# R7FA6M4AF register map
Vendor: Renesas Electronics Corporation; Series: RA6; File version: 1.20.04
CPU: CM33 r0p4, little endian, MPU, FPU, VTOR, 4 interrupt priority bits, 96 interrupts
Registers are 8-bit, read-write, reset 0x0 unless marked. A register's access mark holds for its fields unless they carry their own. Offsets are from the block's base; [hi:lo] are bit positions; {n}, {i} and the like mark numbered series.

## RMPU — Renesas Memory Protection Unit
Base 0x40000000
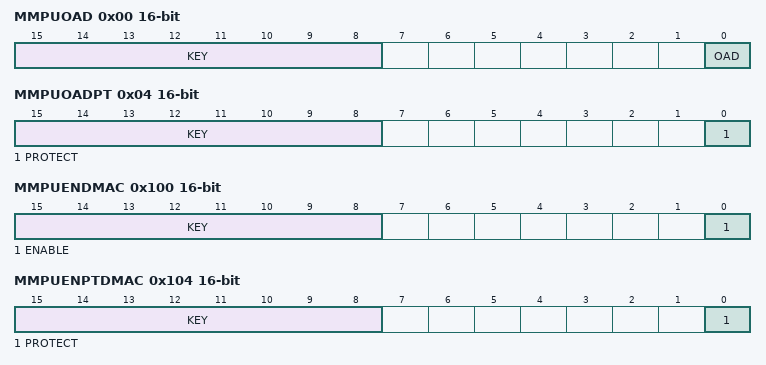
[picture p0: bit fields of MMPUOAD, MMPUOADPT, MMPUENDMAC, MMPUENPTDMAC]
0x00 MMPUOAD 16-bit — MMPU Operation After Detection Register
  [15:8] KEY wo — This bit enables or disables writes to the OAD bit.
  [0] OAD — Operation after detection
    0=Non-maskable interrupt; 1=Reset
0x04 MMPUOADPT 16-bit — MMPU Operation After Detection Protect Register
  [15:8] KEY wo — Key code
  [0] PROTECT — Protection of register
    0=MMPUOAD register writes are possible; 1=MMPUOAD register writes are protected. Read is possible.
0x100 MMPUENDMAC 16-bit — MMPU Enable Register for DMAC
  [15:8] KEY wo — These bits enable or disable writes to the ENABLE bit.
  [0] ENABLE — Bus Master MPU of DMAC enable
    0=Bus Master MPU of DMAC is disabled; 1=Bus Master MPU of DMAC is enabled
0x104 MMPUENPTDMAC 16-bit — MMPU Enable Protect Register for DMAC
  [15:8] KEY wo — These bits enable or disable writes to the PROTECT bit.
  [0] PROTECT — Protection of register
    0=MMPUENDMAC register writes are possible; 1=MMPUENDMAC register writes are protected. Read is possible.
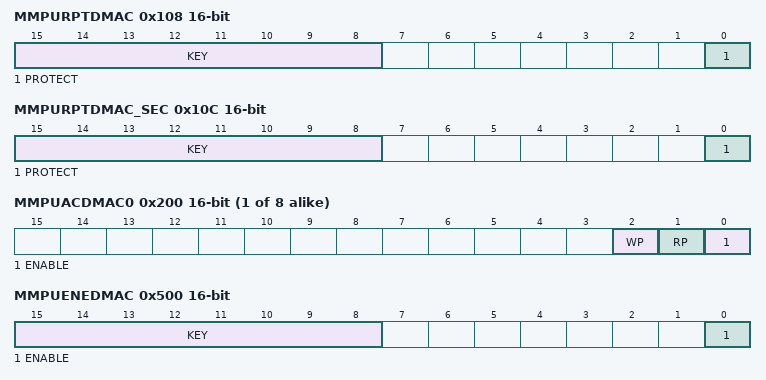
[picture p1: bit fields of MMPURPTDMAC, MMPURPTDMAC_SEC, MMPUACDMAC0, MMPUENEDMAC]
0x108 MMPURPTDMAC 16-bit — MMPU Regions Protect Register for DMAC
  [15:8] KEY wo — These bits enable or disable writes to the PROTECT bit.
  [0] PROTECT — Protection of register
    0=Bus Master MPU register for DMAC writing is possible; 1=Bus Master MPU register for DMAC writing is protected. Read is possible.
0x10C MMPURPTDMAC_SEC 16-bit — MMPU Regions Protect register for DMAC Secure
  [15:8] KEY wo — These bits enable or disable writes to the PROTECT bit.
  [0] PROTECT — Protection of register
    0=Bus master MPU register for DMAC secure writes are possible; 1=Bus master MPU register for DMAC secure writes are protected. Read is possible.
{0x200+0x10*i} MMPUACDMAC{i} (i=0..7) 16-bit — MMPU Access Control Register for DMAC
  [2] WP — Write protection
    0=Write permission; 1=Write protection
  [1] RP — Read protection
    0=Read permission; 1=Read protection
  [0] ENABLE — Region enable
    0=DMAC Region n unit is disabled; 1=DMAC Region n unit is enabled
{0x204+0x10*i} MMPUSDMAC{i} (i=0..7) 32-bit (reset mask 0x1F) — MMPU Start Address Register for DMAC
  [31:5] MMPUS — Region start address register
{0x208+0x10*i} MMPUEDMAC{i} (i=0..7) 32-bit reset 0x1F (reset mask 0x1F) — MMPU End Address Register for DMAC
  [31:5] MMPUE — Region end address register
0x500 MMPUENEDMAC 16-bit — MMPU Enable Register for EDMAC
  [15:8] KEY wo — These bits enable or disable writes to the ENABLE bit.
  [0] ENABLE — Bus Master MPU of EDMAC enable
    0=Bus Master MPU of EDMAC is disabled; 1=Bus Master MPU of EDMAC is enabled
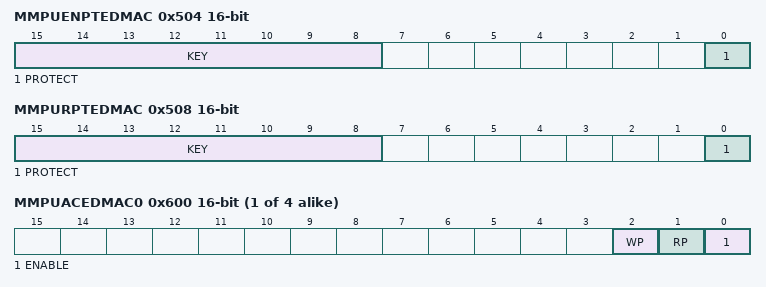
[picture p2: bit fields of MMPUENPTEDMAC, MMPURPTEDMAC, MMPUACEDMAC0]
0x504 MMPUENPTEDMAC 16-bit — MMPU Enable Protect Register for EDMAC
  [15:8] KEY wo — These bits enable or disable writes to the PROTECT bit.
  [0] PROTECT — Protection of register
    0=MMPUENEDMAC register writes are possible; 1=MMPUENEDMAC register writes are protected. Read is possible.
0x508 MMPURPTEDMAC 16-bit — MMPU Regions Protect Register for EDMAC
  [15:8] KEY wo — This bit is used to enable or disable writing of the PROTECT bit.
  [0] PROTECT — Protection of register
    0=Bus Master MPU register for EDMAC writing is possible; 1=Bus Master MPU register for EDMAC writing is protected. Read is possible.
{0x600+0x10*i} MMPUACEDMAC{i} (i=0..3) 16-bit — MMPU Access Control Register for EDMAC
  [2] WP — Write protection
    0=Write permission; 1=Write protection
  [1] RP — Read protection
    0=Read permission; 1=Read protection
  [0] ENABLE — Region enable
    0=EDMAC Region n unit is disabled; 1=EDMAC Region n unit is enabled
{0x604+0x10*i} MMPUSEDMAC{i} (i=0..3) 32-bit (reset mask 0x1F) — MMPU Start Address Register for EDMAC
  [31:5] MMPUS — Region start address register for EDMAC
{0x608+0x10*i} MMPUEEDMAC{i} (i=0..3) 32-bit reset 0x1F (reset mask 0x1F) — MMPU End Address Register for EDMAC
  [31:5] MMPUE — Region end address register for EDMAC

## Notices in the file
This software is supplied by Renesas Electronics Corporation and is only intended for
use with Renesas products. No other uses are authorized. This software is owned by
Renesas Electronics Corporation and is protected under all applicable laws, including
copyright laws.
THIS SOFTWARE IS PROVIDED "AS IS" AND RENESAS MAKES NO WARRANTIES REGARDING
THIS SOFTWARE, WHETHER EXPRESS, IMPLIED OR STATUTORY, INCLUDING BUT NOT LIMITED TO
WARRANTIES OF MERCHANTABILITY, FITNESS FOR A PARTICULAR PURPOSE AND NON-INFRINGEMENT.
ALL SUCH WARRANTIES ARE EXPRESSLY DISCLAIMED. TO THE MAXIMUM EXTENT PERMITTED NOT
PROHIBITED BY LAW, NEITHER RENESAS ELECTRONICS CORPORATION NOR ANY OF ITS AFFILIATED
COMPANIES SHALL BE LIABLE FOR ANY DIRECT, INDIRECT, SPECIAL, INCIDENTAL OR CONSEQUENTIAL
DAMAGES FOR ANY REASON RELATED TO THIS SOFTWARE, EVEN IF RENESAS OR ITS AFFILIATES HAVE
BEEN ADVISED OF THE POSSIBILITY OF SUCH DAMAGES.
Renesas reserves the right, without notice, to make changes to this software and to
discontinue the availability of this software. By using this software, you agree to
the additional terms and conditions found by accessing the following link:
http://www.renesas.com/disclaimer
